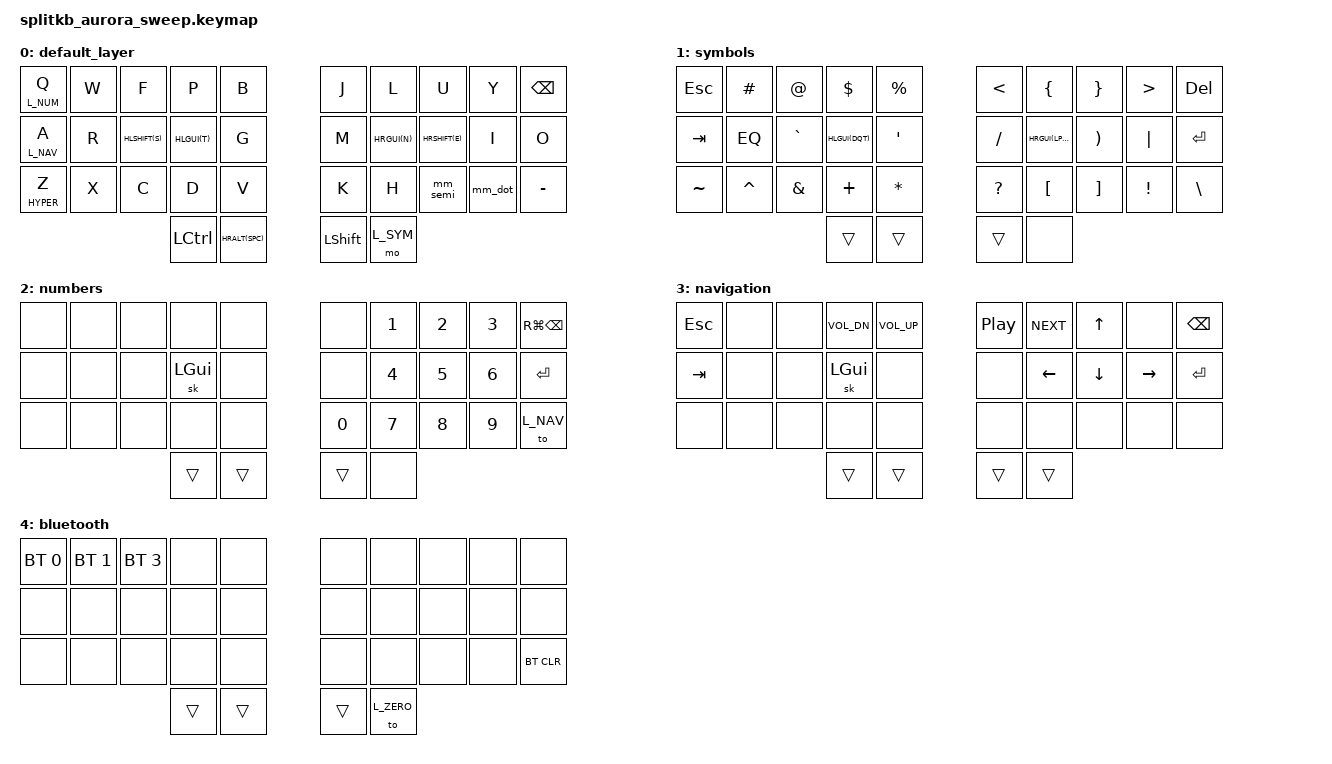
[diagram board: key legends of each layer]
/*
 * Copyright (c) 2022 The ZMK Contributors
 *
 * SPDX-License-Identifier: MIT
 */

#include <behaviors.dtsi>
#include <dt-bindings/zmk/keys.h>
#include <dt-bindings/zmk/bt.h>

#define HOST_OS 2  // set to 2 for macOS/Windows-Alt-Codes, default is 0 (Windows)

#include "../zmk-nodefree-config/helper.h"
#include "../zmk-nodefree-config/international_chars/swedish.dtsi"

#define L_ZERO 0
#define L_SYM 1
#define L_NUM 2
#define L_NAV 3
#define L_BT 4

#define EQ EQUAL

#define HYPER LS(LC(LA(LGUI)))

#define HLCTRL(KEY) &hml LCTRL KEY
#define HLALT(KEY) &hml LALT KEY
#define HLGUI(KEY) &hml LGUI KEY
#define HLSHIFT(KEY) &hml LSHIFT KEY

#define HRCTRL(KEY) &hmr RCTRL KEY
#define HRALT(KEY) &hmr RALT KEY
#define HRGUI(KEY) &hmr RGUI KEY
#define HRSHIFT(KEY) &hmr RSHIFT KEY

#define MOD_MORPH_MASKED(NAME, KEY, MOD_KEY) \
  mm_##NAME: mm_##NAME { \
    compatible = "zmk,behavior-mod-morph"; \
    label = #NAME; \
    #binding-cells = <0>; \
    bindings = <&kp KEY>, <&kp MOD_KEY>; \
    mods = <(MOD_LSFT|MOD_RSFT)>; \
    keep-mods = <(MOD_LSFT|MOD_RSFT)>; \
  };

#define MOD_MORPH(NAME, KEY, MOD_KEY) \
  mm_##NAME: mm_##NAME { \
    compatible = "zmk,behavior-mod-morph"; \
    label = #NAME; \
    #binding-cells = <0>; \
    bindings = <&kp KEY>, <&kp MOD_KEY>; \
    mods = <(MOD_LSFT|MOD_RSFT)>; \
  };

&mt {
  flavor = "tap-preferred";
  tapping_term_ms = <200>;
};

/ {
    combos {
      compatible = "zmk,combos";
      combo_sys {
        timeout-ms = <30>;
        key-positions = <0 1 2 3>;
        bindings = <&to L_BT>;
      };
      // combo_aring {
      //   timeout-ms = <30>;
      //   key-positions = <3 4>;
      //   bindings = <&sv_ae>;
      // };
      // combo_auml {
      //   timeout-ms = <30>;
      //   key-positions = <23 24>;
      //   bindings = <&sv_ao>;
      // };
      // combo_ouml {
      //   timeout-ms = <30>;
      //   key-positions = <25 26>;
      //   bindings = <&sv_oe>;
      // };
    };

    behaviors {
      hml: homerow_mods_left {
        compatible = "zmk,behavior-hold-tap";
        label = "HOMEROW_MODS_LEFT";
        #binding-cells = <2>;
        tapping-term-ms = <200>;
        quick-tap-ms = <125>;
        flavor = "tap-preferred";
        bindings = <&kp>, <&kp>;
      };
    
      hmr: homerow_mods_right {
        compatible = "zmk,behavior-hold-tap";
        label = "HOMEROW_MODS_RIGHT";
        #binding-cells = <2>;
        tapping-term-ms = <200>;
        quick-tap-ms = <125>;
        flavor = "tap-preferred";
        
        bindings = <&kp>, <&kp>;
      };

      MOD_MORPH(semi, COMMA, SEMICOLON)
      MOD_MORPH(dot, DOT, COLON)
    };

    keymap {
      compatible = "zmk,keymap";

      default_layer {
        bindings = <
        //  pos 0        pos 1        pos 2        pos 3        pos 4      |    pos 5       pos 6        pos 7        pos 8        pos 9
        &lt L_NUM Q      &kp W        &kp F        &kp P        &kp B           &kp J       &kp L        &kp U        &kp Y        &kp BSPC
        //  pos 10       pos 11       pos 12       pos 13       pos 14     |    pos 15      pos 16       pos 17       pos 18       pos 19 
        &lt L_NAV A      &kp R        HLSHIFT(S)   HLGUI(T)     &kp G           &kp M       HRGUI(N)     HRSHIFT(E)   &kp I        &kp O
        //  pos 20       pos 21       pos 22       pos 23       pos 24     |    pos 25      pos 26       pos 27       pos 28       pos 29 
        &mt HYPER Z      &kp X        &kp C        &kp D        &kp V           &kp K       &kp H        &mm_semi     &mm_dot      &kp MINUS
        //                                         pos 30       pos 31     |    pos 32      pos 33
                                                   &kp LCTRL    HRALT(SPC)      &kp LSHIFT  &mo L_SYM
        >;
      };

      symbols {
        bindings = <
        //  pos 0        pos 1        pos 2        pos 3        pos 4      |    pos 5       pos 6        pos 7        pos 8        pos 9
        &kp ESC          &kp HASH     &kp AT       &kp DLLR     &kp PRCNT       &kp LT      &kp LBRC     &kp RBRC     &kp GT       &kp DEL
        //  pos 10       pos 11       pos 12       pos 13       pos 14     |    pos 15      pos 16       pos 17       pos 18       pos 19 
        &kp TAB          &kp EQ       &kp GRAVE    HLGUI(DQT)   &kp SQT         &kp SLASH   HRGUI(LPAR)  &kp RPAR     &kp PIPE     &kp ENTER
        //  pos 20       pos 21       pos 22       pos 23       pos 24     |    pos 25      pos 26       pos 27       pos 28       pos 29 
        &kp TILDE        &kp CARET    &kp AMPS     &kp PLUS     &kp STAR        &kp QMARK   &kp LBKT     &kp RBKT    &kp EXCL     &kp BSLH
        //                                         pos 30       pos 31     |    pos 32      pos 33
                                                   &trans       &trans          &trans      &none
        >;
      };

      numbers {
        bindings = <
        //  pos 0        pos 1        pos 2        pos 3        pos 4      |    pos 5       pos 6        pos 7        pos 8        pos 9
        &none            &none        &none        &none        &none           &none       &kp N1       &kp N2       &kp N3       &kp RG(BSPC)
        //  pos 10       pos 11       pos 12       pos 13       pos 14     |    pos 15      pos 16       pos 17       pos 18       pos 19 
        &none            &none        &none        &sk LGUI     &none           &none       &kp N4       &kp N5       &kp N6       &kp ENTER
        //  pos 20       pos 21       pos 22       pos 23       pos 24     |    pos 25      pos 26       pos 27       pos 28       pos 29 
        &none            &none        &none        &none        &none           &kp N0      &kp N7       &kp N8       &kp N9       &to L_NAV
        //                                         pos 30       pos 31     |    pos 32      pos 33
                                                   &trans       &trans          &trans      &none
        >;
      };

      navigation {
        bindings = <
        //  pos 0        pos 1        pos 2        pos 3        pos 4      |    pos 5       pos 6        pos 7        pos 8        pos 9
        &kp ESC          &none        &none        &kp C_VOL_DN &kp C_VOL_UP    &kp C_PP    &kp C_NEXT   &kp UP       &none        &kp BSPC
        //  pos 10       pos 11       pos 12       pos 13       pos 14     |    pos 15      pos 16       pos 17       pos 18       pos 19 
        &kp TAB          &none        &none        &sk LGUI     &none           &none       &kp LEFT     &kp DOWN     &kp RIGHT    &kp ENTER
        //  pos 20       pos 21       pos 22       pos 23       pos 24     |    pos 25      pos 26       pos 27       pos 28       pos 29 
        &none            &none        &none        &none        &none           &none       &none        &none        &none        &none
        //                                         pos 30       pos 31     |    pos 32      pos 33
                                                   &trans       &trans          &trans      &trans
        >;
      };

      bluetooth {
        bindings = <
        //  pos 0        pos 1        pos 2        pos 3        pos 4      |    pos 5       pos 6        pos 7        pos 8        pos 9
        &bt BT_SEL 0     &bt BT_SEL 1 &bt BT_SEL 3 &none        &none           &none       &none        &none        &none        &none
        //  pos 10       pos 11       pos 12       pos 13       pos 14     |    pos 15      pos 16       pos 17       pos 18       pos 19 
        &none            &none        &none        &none        &none           &none       &none        &none        &none        &none
        //  pos 20       pos 21       pos 22       pos 23       pos 24     |    pos 25      pos 26       pos 27       pos 28       pos 29 
        &none            &none        &none        &none        &none           &none       &none        &none        &none        &bt BT_CLR
        //                                         pos 30       pos 31     |    pos 32      pos 33
                                                   &trans       &trans          &trans      &to L_ZERO
        >;
      };

    };
  };

